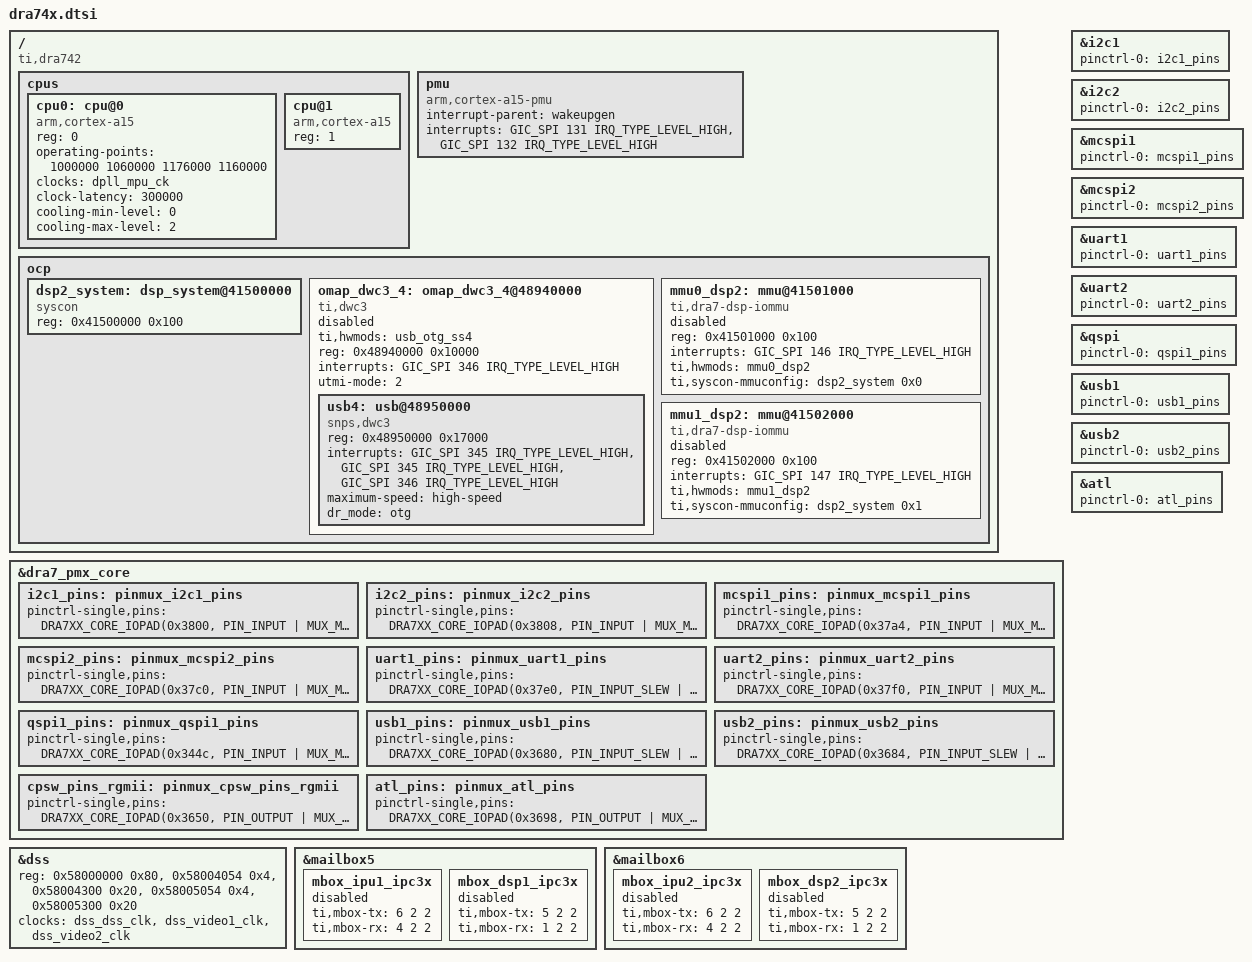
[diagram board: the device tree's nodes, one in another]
/*
 * Copyright (C) 2014 Texas Instruments Incorporated - http://www.ti.com/
 *
 * This program is free software; you can redistribute it and/or modify
 * it under the terms of the GNU General Public License version 2 as
 * published by the Free Software Foundation.
 * Based on "omap4.dtsi"
 */

#include "dra7.dtsi"

/ {
	compatible = "ti,dra742", "ti,dra74", "ti,dra7";

	cpus {
		#address-cells = <1>;
		#size-cells = <0>;

		cpu0: cpu@0 {
			device_type = "cpu";
			compatible = "arm,cortex-a15";
			reg = <0>;

			operating-points = <
				/* kHz    uV */
				1000000	1060000
				1176000	1160000
				>;

			clocks = <&dpll_mpu_ck>;
			clock-names = "cpu";

			clock-latency = <300000>; /* From omap-cpufreq driver */

			/* cooling options */
			cooling-min-level = <0>;
			cooling-max-level = <2>;
			#cooling-cells = <2>; /* min followed by max */
		};
		cpu@1 {
			device_type = "cpu";
			compatible = "arm,cortex-a15";
			reg = <1>;
		};
	};

	pmu {
		compatible = "arm,cortex-a15-pmu";
		interrupt-parent = <&wakeupgen>;
		interrupts = <GIC_SPI 131 IRQ_TYPE_LEVEL_HIGH>,
			     <GIC_SPI 132 IRQ_TYPE_LEVEL_HIGH>;
	};

	ocp {
		dsp2_system: dsp_system@41500000 {
			compatible = "syscon";
			reg = <0x41500000 0x100>;
		};

		omap_dwc3_4: omap_dwc3_4@48940000 {
			compatible = "ti,dwc3";
			ti,hwmods = "usb_otg_ss4";
			reg = <0x48940000 0x10000>;
			interrupts = <GIC_SPI 346 IRQ_TYPE_LEVEL_HIGH>;
			#address-cells = <1>;
			#size-cells = <1>;
			utmi-mode = <2>;
			ranges;
			status = "disabled";
			usb4: usb@48950000 {
				compatible = "snps,dwc3";
				reg = <0x48950000 0x17000>;
				interrupts = <GIC_SPI 345 IRQ_TYPE_LEVEL_HIGH>,
					     <GIC_SPI 345 IRQ_TYPE_LEVEL_HIGH>,
					     <GIC_SPI 346 IRQ_TYPE_LEVEL_HIGH>;
				interrupt-names = "peripheral",
						  "host",
						  "otg";
				maximum-speed = "high-speed";
				dr_mode = "otg";
			};
		};

		mmu0_dsp2: mmu@41501000 {
			compatible = "ti,dra7-dsp-iommu";
			reg = <0x41501000 0x100>;
			interrupts = <GIC_SPI 146 IRQ_TYPE_LEVEL_HIGH>;
			ti,hwmods = "mmu0_dsp2";
			#iommu-cells = <0>;
			ti,syscon-mmuconfig = <&dsp2_system 0x0>;
			status = "disabled";
		};

		mmu1_dsp2: mmu@41502000 {
			compatible = "ti,dra7-dsp-iommu";
			reg = <0x41502000 0x100>;
			interrupts = <GIC_SPI 147 IRQ_TYPE_LEVEL_HIGH>;
			ti,hwmods = "mmu1_dsp2";
			#iommu-cells = <0>;
			ti,syscon-mmuconfig = <&dsp2_system 0x1>;
			status = "disabled";
		};
	};
};

&dra7_pmx_core {
	i2c1_pins: pinmux_i2c1_pins {
		pinctrl-single,pins = <
			DRA7XX_CORE_IOPAD(0x3800, PIN_INPUT | MUX_MODE0) /* i2c1_sda */
			DRA7XX_CORE_IOPAD(0x3804, PIN_INPUT | MUX_MODE0) /* i2c1_scl */
		>;
	};

	i2c2_pins: pinmux_i2c2_pins {
		pinctrl-single,pins = <
			DRA7XX_CORE_IOPAD(0x3808, PIN_INPUT | MUX_MODE0) /* i2c2_sda */
			DRA7XX_CORE_IOPAD(0x380c, PIN_INPUT | MUX_MODE0) /* i2c2_scl */
		>;
	};

	mcspi1_pins: pinmux_mcspi1_pins {
		pinctrl-single,pins = <
			DRA7XX_CORE_IOPAD(0x37a4, PIN_INPUT | MUX_MODE0) /* spi1_sclk */
			DRA7XX_CORE_IOPAD(0x37a8, PIN_INPUT | MUX_MODE0) /* spi1_d1 */
			DRA7XX_CORE_IOPAD(0x37ac, PIN_INPUT | MUX_MODE0) /* spi1_d0 */
			DRA7XX_CORE_IOPAD(0x37b0, PIN_INPUT_SLEW | MUX_MODE0) /* spi1_cs0 */
			DRA7XX_CORE_IOPAD(0x37b8, PIN_INPUT_SLEW | MUX_MODE6) /* spi1_cs2.hdmi1_hpd */
			DRA7XX_CORE_IOPAD(0x37bc, PIN_INPUT_SLEW | MUX_MODE6) /* spi1_cs3.hdmi1_cec */
		>;
	};

	mcspi2_pins: pinmux_mcspi2_pins {
		pinctrl-single,pins = <
			DRA7XX_CORE_IOPAD(0x37c0, PIN_INPUT | MUX_MODE0) /* spi2_sclk */
			DRA7XX_CORE_IOPAD(0x37c4, PIN_INPUT_SLEW | MUX_MODE0) /* spi2_d1 */
			DRA7XX_CORE_IOPAD(0x37c8, PIN_INPUT_SLEW | MUX_MODE0) /* spi2_d1 */
			DRA7XX_CORE_IOPAD(0x37cc, PIN_INPUT_SLEW | MUX_MODE0) /* spi2_cs0 */
		>;
	};

	uart1_pins: pinmux_uart1_pins {
		pinctrl-single,pins = <
			DRA7XX_CORE_IOPAD(0x37e0, PIN_INPUT_SLEW | MUX_MODE0) /* uart1_rxd */
			DRA7XX_CORE_IOPAD(0x37e4, PIN_INPUT_SLEW | MUX_MODE0) /* uart1_txd */
			DRA7XX_CORE_IOPAD(0x37e8, PIN_INPUT | MUX_MODE3) /* uart1_ctsn */
			DRA7XX_CORE_IOPAD(0x37ec, PIN_INPUT | MUX_MODE3) /* uart1_rtsn */
		>;
	};

	uart2_pins: pinmux_uart2_pins {
		pinctrl-single,pins = <
			DRA7XX_CORE_IOPAD(0x37f0, PIN_INPUT | MUX_MODE0) /* uart2_rxd */
			DRA7XX_CORE_IOPAD(0x37f4, PIN_INPUT | MUX_MODE0) /* uart2_txd */
			DRA7XX_CORE_IOPAD(0x37f8, PIN_INPUT | MUX_MODE0) /* uart2_ctsn */
			DRA7XX_CORE_IOPAD(0x37fc, PIN_INPUT | MUX_MODE0) /* uart2_rtsn */
		>;
	};

	qspi1_pins: pinmux_qspi1_pins {
		pinctrl-single,pins = <
			DRA7XX_CORE_IOPAD(0x344c, PIN_INPUT | MUX_MODE1)  /* gpmc_a3.qspi1_cs2 */
			DRA7XX_CORE_IOPAD(0x3450, PIN_INPUT | MUX_MODE1)  /* gpmc_a4.qspi1_cs3 */
			DRA7XX_CORE_IOPAD(0x3474, PIN_INPUT | MUX_MODE1)  /* gpmc_a13.qspi1_rtclk */
			DRA7XX_CORE_IOPAD(0x3478, PIN_INPUT | MUX_MODE1)  /* gpmc_a14.qspi1_d3 */
			DRA7XX_CORE_IOPAD(0x347c, PIN_INPUT | MUX_MODE1)  /* gpmc_a15.qspi1_d2 */
			DRA7XX_CORE_IOPAD(0x3480, PIN_INPUT | MUX_MODE1) /* gpmc_a16.qspi1_d1 */
			DRA7XX_CORE_IOPAD(0x3484, PIN_INPUT | MUX_MODE1)  /* gpmc_a17.qspi1_d0 */
			DRA7XX_CORE_IOPAD(0x3488, PIN_INPUT | MUX_MODE1)  /* qpmc_a18.qspi1_sclk */
			DRA7XX_CORE_IOPAD(0x34b8, PIN_INPUT_PULLUP | MUX_MODE1)  /* gpmc_cs2.qspi1_cs0 */
			DRA7XX_CORE_IOPAD(0x34bc, PIN_INPUT_PULLUP | MUX_MODE1)  /* gpmc_cs3.qspi1_cs1 */
		>;
	};

	usb1_pins: pinmux_usb1_pins {
                pinctrl-single,pins = <
			DRA7XX_CORE_IOPAD(0x3680, PIN_INPUT_SLEW | MUX_MODE0) /* usb1_drvvbus */
                >;
        };

	usb2_pins: pinmux_usb2_pins {
                pinctrl-single,pins = <
			DRA7XX_CORE_IOPAD(0x3684, PIN_INPUT_SLEW | MUX_MODE0) /* usb2_drvvbus */
                >;
        };

	cpsw_pins_rgmii: pinmux_cpsw_pins_rgmii {
		pinctrl-single,pins = <
			/* Slave 1 */
			DRA7XX_CORE_IOPAD(0x3650, PIN_OUTPUT | MUX_MODE0)	/* rgmii0_txc.rgmii0_txc */
			DRA7XX_CORE_IOPAD(0x3654, PIN_OUTPUT | MUX_MODE0)	/* rgmii0_txctl.rgmii0_txctl */
			DRA7XX_CORE_IOPAD(0x3658, PIN_OUTPUT | MUX_MODE0)	/* rgmii0_td3.rgmii0_txd3 */
			DRA7XX_CORE_IOPAD(0x365c, PIN_OUTPUT | MUX_MODE0)	/* rgmii0_txd2.rgmii0_txd2 */
			DRA7XX_CORE_IOPAD(0x3660, PIN_OUTPUT | MUX_MODE0)	/* rgmii0_txd1.rgmii0_txd1 */
			DRA7XX_CORE_IOPAD(0x3664, PIN_OUTPUT | MUX_MODE0)	/* rgmii0_txd0.rgmii0_txd0 */
			DRA7XX_CORE_IOPAD(0x3668, PIN_INPUT | MUX_MODE0)	/* rgmii0_rxc.rgmii0_rxc */
			DRA7XX_CORE_IOPAD(0x366c, PIN_INPUT | MUX_MODE0)	/* rgmii0_rxctl.rgmii0_rxctl */
			DRA7XX_CORE_IOPAD(0x3670, PIN_INPUT | MUX_MODE0)	/* rgmii0_rxd3.rgmii0_rxd3 */
			DRA7XX_CORE_IOPAD(0x3674, PIN_INPUT | MUX_MODE0)	/* rgmii0_rxd2.rgmii0_rxd2 */
			DRA7XX_CORE_IOPAD(0x3678, PIN_INPUT | MUX_MODE0)	/* rgmii0_rxd1.rgmii0_rxd1 */
			DRA7XX_CORE_IOPAD(0x367c, PIN_INPUT | MUX_MODE0)	/* rgmii0_rxd0.rgmii0_rxd0 */

			/* Slave 2 */
			DRA7XX_CORE_IOPAD(0x3598, PIN_OUTPUT | MUX_MODE3)	/* vin2a_d12.rgmii1_txc */
			DRA7XX_CORE_IOPAD(0x359c, PIN_OUTPUT | MUX_MODE3)	/* vin2a_d13.rgmii1_tctl */
			DRA7XX_CORE_IOPAD(0x35a0, PIN_OUTPUT | MUX_MODE3)	/* vin2a_d14.rgmii1_td3 */
			DRA7XX_CORE_IOPAD(0x35a4, PIN_OUTPUT | MUX_MODE3)	/* vin2a_d15.rgmii1_td2 */
			DRA7XX_CORE_IOPAD(0x35a8, PIN_OUTPUT | MUX_MODE3)	/* vin2a_d16.rgmii1_td1 */
			DRA7XX_CORE_IOPAD(0x35ac, PIN_OUTPUT | MUX_MODE3)	/* vin2a_d17.rgmii1_td0 */
			DRA7XX_CORE_IOPAD(0x35b0, PIN_INPUT | MUX_MODE3)	/* vin2a_d18.rgmii1_rclk */
			DRA7XX_CORE_IOPAD(0x35b4, PIN_INPUT | MUX_MODE3)	/* vin2a_d19.rgmii1_rctl */
			DRA7XX_CORE_IOPAD(0x35b8, PIN_INPUT | MUX_MODE3)	/* vin2a_d20.rgmii1_rd3 */
			DRA7XX_CORE_IOPAD(0x35bc, PIN_INPUT | MUX_MODE3)	/* vin2a_d21.rgmii1_rd2 */
			DRA7XX_CORE_IOPAD(0x35c0, PIN_INPUT | MUX_MODE3)	/* vin2a_d22.rgmii1_rd1 */
			DRA7XX_CORE_IOPAD(0x35c4, PIN_INPUT | MUX_MODE3)	/* vin2a_d23.rgmii1_rd0 */
		>;

	};

	atl_pins: pinmux_atl_pins {
		pinctrl-single,pins = <
			DRA7XX_CORE_IOPAD(0x3698, PIN_OUTPUT | MUX_MODE5)	/* xref_clk1.atl_clk1 */
			DRA7XX_CORE_IOPAD(0x369c, PIN_OUTPUT | MUX_MODE5)	/* xref_clk2.atl_clk2 */
		>;
	};
};

&dss {
	reg = <0x58000000 0x80>,
	      <0x58004054 0x4>,
	      <0x58004300 0x20>,
	      <0x58005054 0x4>,
	      <0x58005300 0x20>;
	reg-names = "dss", "pll1_clkctrl", "pll1",
		    "pll2_clkctrl", "pll2";

	clocks = <&dss_dss_clk>,
		 <&dss_video1_clk>,
		 <&dss_video2_clk>;
	clock-names = "fck", "video1_clk", "video2_clk";
};

&mailbox5 {
	mbox_ipu1_ipc3x: mbox_ipu1_ipc3x {
		ti,mbox-tx = <6 2 2>;
		ti,mbox-rx = <4 2 2>;
		status = "disabled";
	};
	mbox_dsp1_ipc3x: mbox_dsp1_ipc3x {
		ti,mbox-tx = <5 2 2>;
		ti,mbox-rx = <1 2 2>;
		status = "disabled";
	};
};

&i2c1 {
	pinctrl-names = "default";
	pinctrl-0 = <&i2c1_pins>;
};

&i2c2 {
	pinctrl-names = "default";
	pinctrl-0 = <&i2c2_pins>;
};

&mcspi1 {
	pinctrl-names = "default";
	pinctrl-0 = <&mcspi1_pins>;
};

&mcspi2 {
	pinctrl-names = "default";
	pinctrl-0 = <&mcspi2_pins>;
};

&uart1 {
	pinctrl-names = "default";
	pinctrl-0 = <&uart1_pins>;
};

&uart2 {
	pinctrl-names = "default";
	pinctrl-0 = <&uart2_pins>;
};

&qspi {
	pinctrl-names = "default";
	pinctrl-0 = <&qspi1_pins>;
};

&usb1 {
	pinctrl-names = "default";
	pinctrl-0 = <&usb1_pins>;
};

&usb2 {
	pinctrl-names = "default";
	pinctrl-0 = <&usb2_pins>;
};

&atl {
	pinctrl-names = "default";
	pinctrl-0 = <&atl_pins>;
};

&mailbox6 {
	mbox_ipu2_ipc3x: mbox_ipu2_ipc3x {
		ti,mbox-tx = <6 2 2>;
		ti,mbox-rx = <4 2 2>;
		status = "disabled";
	};
	mbox_dsp2_ipc3x: mbox_dsp2_ipc3x {
		ti,mbox-tx = <5 2 2>;
		ti,mbox-rx = <1 2 2>;
		status = "disabled";
	};
};
